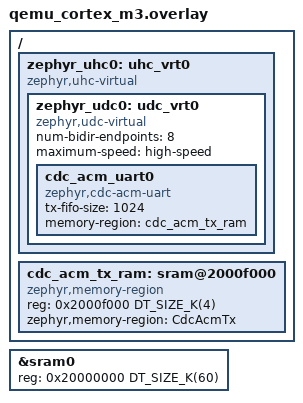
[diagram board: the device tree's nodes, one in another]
/*
 * SPDX-FileCopyrightText: Copyright The Zephyr Project Contributors
 * SPDX-License-Identifier: Apache-2.0
 */

#include <mem.h>

/ {
	zephyr_uhc0: uhc_vrt0 {
		compatible = "zephyr,uhc-virtual";

		zephyr_udc0: udc_vrt0 {
			compatible = "zephyr,udc-virtual";
			num-bidir-endpoints = <8>;
			maximum-speed = "high-speed";

			cdc_acm_uart0: cdc_acm_uart0 {
				compatible = "zephyr,cdc-acm-uart";
				tx-fifo-size = <1024>;
				memory-region = <&cdc_acm_tx_ram>;
			};
		};
	};

	cdc_acm_tx_ram: sram@2000f000 {
		compatible = "zephyr,memory-region", "mmio-sram";
		reg = <0x2000f000 DT_SIZE_K(4)>;
		zephyr,memory-region = "CdcAcmTx";
	};
};

&sram0 {
	reg = <0x20000000 DT_SIZE_K(60)>;
};
